# RS1xxxx register map
Vendor: Silicon Lab Inc.; Series: ARMCM4; File version: 1.2
CPU: CM4 r1p0, little endian, MPU, FPU, 6 interrupt priority bits
Registers are 32-bit, read-write, reset 0x0 unless marked. A register's access mark holds for its fields unless they carry their own. Offsets are from the block's base; [hi:lo] are bit positions; lines under a group give offsets from that group; {n}, {i} and the like mark numbered series; 'fields as' and 'values as' point back to an identical list.

## UDMA0 — DMA Performs data transfers along with Addresses and control information
Base 0x44030000
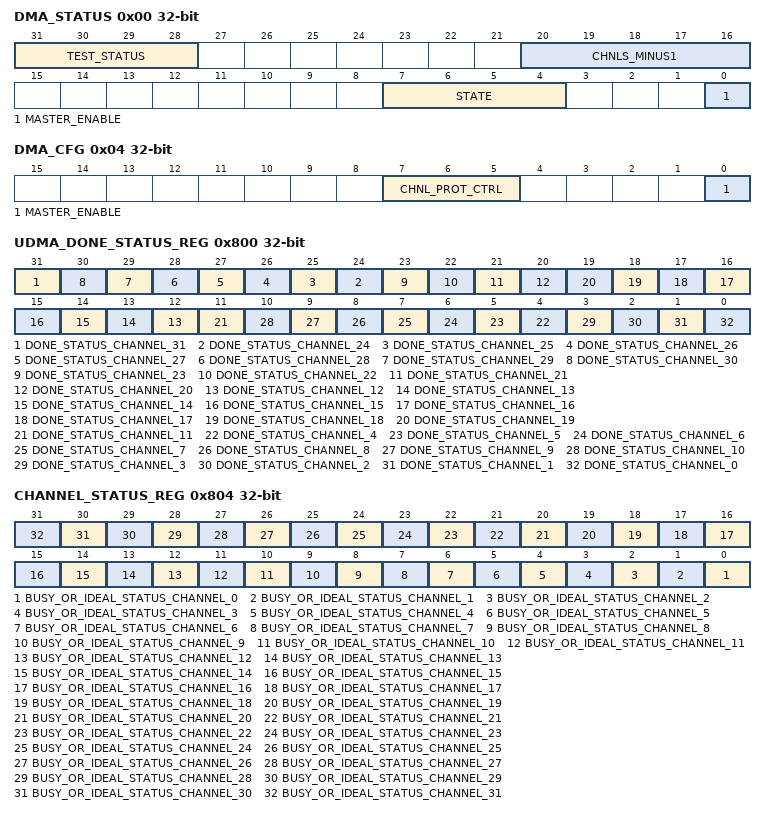
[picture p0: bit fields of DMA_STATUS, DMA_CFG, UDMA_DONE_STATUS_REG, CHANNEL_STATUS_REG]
0x00 DMA_STATUS ro — UDMA Status Register
  [31:28] TEST_STATUS — To reduce the gate count you can configure the controller
    0=Controller does not includes integration test logic; 1=Controller does not includes integration test logic
  [20:16] CHNLS_MINUS1 — Number of available DMA channels minus one
  [7:4] STATE — Current state of the control state machine
  [0] MASTER_ENABLE — Enable status of controller
    0=Disable (controller is disable); 1=Enable (controller is enable)
0x04 DMA_CFG wo — DMA Configuration
  [7:5] CHNL_PROT_CTRL — Sets the AHB-Lite protection by controlling the HPROT[3:1]] signal levels as follows Bit[7]-Controls HPROT[3] to indicate if cacheable access is occurring Bit[6]-Controls HPROT[2] to indicate if cacheable access is occurring Bit[5]-Controls HPROT[1] to indicate if cacheable access is occurring
  [0] MASTER_ENABLE — Enable for the controller
    values as DMA_STATUS.MASTER_ENABLE
0x08 CTRL_BASE_PTR — Channel Control Data Base Pointer
  [31:10] CTRL_BASE_PTR — Pointer to the base address of the primary data structure
0x0C ALT_CTRL_BASE_PTR ro — Channel Alternate Control Data Base Pointer
  [31:0] ALT_CTRL_BASE_PTR — Base address of the alternative data structure
0x10 DMA_WAITONREQUEST_STATUS ro — Channel Wait on request status register
  [31:0] DMA_WAITONREQ_STATUS — Per Channel wait on request status
0x14 CHNL_SW_REQUEST wo — Channel Software Request
  [31:0] CHNL_SW_REQUEST — Set the appropriate bit to generate a software DMA request on the corresponding DMA channel
0x18 CHNL_USEBURST_SET — UDMA Channel use burst set
  [31:0] CHNL_USEBURST_SET — The use burst status, or disables dma_sreq[C] from generating DMA requests.
0x1C CHNL_USEBURST_CLR wo — UDMA Channel use burst clear
  [31:0] CHNL_USEBURST_CLR — Set the appropriate bit to enable dma_sreq[] to generate requests
0x20 CHNL_REQ_MASK_SET — UDMA Channel request mask set Register
  [31:0] CHNL_REQ_MASK_SET — Returns the request mask status of dma_req[] and dma_sreq[], or disables the corresponding channel from generating DMA requests
0x24 CHNL_REQ_MASK_CLR wo — UDMA Channel request mask clear
  [31:0] CHNL_REQ_MASK_CLR — Set the appropriate bit to enable DMA requests for the channel corresponding to dma_req[] and dma_sreq[]
0x28 CHNL_ENABLE_SET — UDMA Channel enable register
  [31:0] CHNL_ENABLE_SET — This Bits are Used to Load the 16bits of Source address
0x2C CHNL_ENABLE_CLR wo — UDMA Channel enable clear register
  [31:0] CHNL_ENABLE_CLR — Set the appropriate bit to disable the corresponding DMA channel
0x30 CHNL_PRI_ALT_SET — UDMA Channel primary or alternate set
  [31:0] CHNL_PRI_ALT_SET — Returns the channel control data structure status or selects the alternate data structure for the corresponding DMA channel
0x34 CHNL_PRI_ALT_CLR wo — UDMA Channel primary alternate clear
  [31:0] CHNL_PRI_ALT_CLR — Set the appropriate bit to select the primary data structure for the corresponding DMA channel
0x38 CHNL_PRIORITY_SET — UDMA Channel Priority Set
  [31:0] CHNL_PRIORITY_SET — Set the appropriate bit to select the primary data structure for the corresponding DMA channel
0x3C CHNL_PRIORITY_CLR wo — UDMA Channel Priority Clear
  [31:0] CHNL_PRIORITY_CLR — Set the appropriate bit to select the default priority level for the specified DMA channel
0x4C ERR_CLR — UDMA Bus Error Clear Register
  [0] ERR_CLR — Returns the status of dma_err
    0=disabled (Read as:0 = dma_err is LOW Write as:0 = No effect, status of dma_err is unchanged); 1=enabled (Read as:1 = dma_err is HIGH Write as:1 = Sets dma_err LOW)
0x50 UDMA_SKIP_DESC_FETCH_REG (reset mask 0x1) — UDMA skip descriptor fetch Register
  [31:0] SKIP_DESC_FETCH — improving the performance of transfer and saves bus cycles. This features has to be enabled always.
0x800 UDMA_DONE_STATUS_REG — UDMA Done status Register
  [31] DONE_STATUS_CHANNEL_31 — UDMA done Status of the channel 31
    0=disabled (Write as:0 will have no effect); 1=enabled (Read as:1 indicates the transfer is completed for channel 31st Write as:1 will clear the bit)
  [n] DONE_STATUS_CHANNEL_{n} (n=24..30) — UDMA done Status of the channel {n}
    0=disabled (Write as:0 will have no effect); 1=enabled (Read as:1 indicates the transfer is completed for channel {n}th Write as:1 will clear the bit)
  [23] DONE_STATUS_CHANNEL_23 — UDMA done Status of the channel 23
    0=disabled (Write as:0 will have no effect); 1=enabled (Read as:1 indicates the transfer is completed for channel 23rd Write as:1 will clear the bit)
  [22] DONE_STATUS_CHANNEL_22 — UDMA done Status of the channel 22
    0=disabled (Write as:0 will have no effect); 1=enabled (Read as:1 indicates the transfer is completed for channel 22th Write as:1 will clear the bit)
  [21] DONE_STATUS_CHANNEL_21 — UDMA done Status of the channel 21
    0=disabled (Write as:0 will have no effect); 1=enabled (Read as:1 indicates the transfer is completed for channel 21th Write as:1 will clear the bit)
  [20] DONE_STATUS_CHANNEL_20 — UDMA done Status of the channel 3
    0=disabled (Write as:0 will have no effect); 1=enabled (Read as:1 indicates the transfer is completed for channel 20th Write as:1 will clear the bit)
  [n] DONE_STATUS_CHANNEL_{n} (n=12..19) — UDMA done Status of the channel {n}
    values as DONE_STATUS_CHANNEL_24
  [11] DONE_STATUS_CHANNEL_11 — UDMA done Status of the channel 3
    0=disabled (Write as:0 will have no effect); 1=enabled (Read as:1 indicates the transfer is completed for channel 11th Write as:1 will clear the bit)
  [n] DONE_STATUS_CHANNEL_{n} (n=4..10) — UDMA done Status of the channel {n}
    values as DONE_STATUS_CHANNEL_24
  [3] DONE_STATUS_CHANNEL_3 — UDMA done Status of the channel 3
    0=disabled (Write as:0 will have no effect); 1=enabled (Read as:1 indicates the transfer is completed for channel 3rd Write as:1 will clear the bit)
  [2] DONE_STATUS_CHANNEL_2 — UDMA done Status of the channel 2
    0=disabled (Write as:0 will have no effect); 1=enabled (Read as:1 indicates the transfer is completed for channel 2nd Write as:1 will clear the bit)
  [1] DONE_STATUS_CHANNEL_1 — UDMA done Status of the channel 1
    0=disabled (Write as:0 will have no effect); 1=enabled (Read as:1 indicates the transfer is completed for channel 1st Write as:1 will clear the bit)
  [0] DONE_STATUS_CHANNEL_0 — UDMA done Status of the channel 0
    0=disabled (Write as:0 will have no effect); 1=enabled (Read as:1 indicates the transfer is completed for channel 0th Write as:1 will clear the bit)
0x804 CHANNEL_STATUS_REG ro — Channel status Register
  [n] BUSY_OR_IDEAL_STATUS_CHANNEL_{n} (n=0..31) — Reading 1 indicates that the channel {n} is busy
{0x808+4i} UDMA_PERIPHERAL_SEL_CHn_REG[{i}] (i=0..7) group — Peripheral select channel register channels 0 - 7
  0x00 Peripheral_Select_CH__n_ (reset mask 0xF) — peripheral select for channel _n_
    [4:0] peripheral_select_channel_n_
0x828 UDMA_CONFIG_CTRL_REG — DMA Controller Transfer Length Register
  [0] SINGLE_REQUEST_ENABLE — Enabled signal for single request
    0=disabled (Single request will be disabled); 1=enabled (Single request will be enabled)

## UDMA1 — DMA Performs data transfers along with Addresses and control information
Base 0x24078000
Registers as UDMA0, without UDMA_PERIPHERAL_SEL_CHn_REG; these are added or differ:
0x82C UDMA_INTR_MASK_REG — Mask the uDMA interrupt register
  [11:0] UDMA_INTR_MASK
